# CPU_ROM_TABLE register map
Vendor: Texas Instruments
Peripheral module from a debugger description file (folder UCD3138R032RJA).
Registers are 32-bit, read-only, reset 0x0 unless marked. A register's access mark holds for its fields unless they carry their own. Offsets are as the file gives them; lines under a group give offsets from that group; [hi:lo] are bit positions; {n}, {i} and the like mark numbered series; 'fields as' and 'values as' point back to an identical list; <NAME> marks a mode.

## CPU_ROM_TABLE
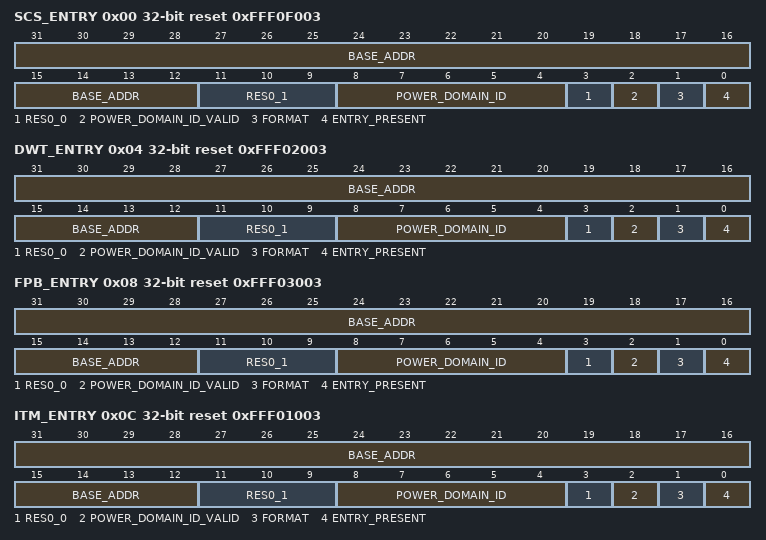
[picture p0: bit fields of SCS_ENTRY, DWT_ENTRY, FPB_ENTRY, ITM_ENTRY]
0x00 SCS_ENTRY reset 0xFFF0F003 — SCS component
  [31:12] BASE_ADDR — Base address for master interface 0. Bit[31] is always 0.
  [11:9] RES0_1 — Reserved, RES0
  [8:4] POWER_DOMAIN_ID — Indicates the power domain ID of the component. This field is only valid when bit[2] of this register is 0b1. Otherwise this field is 0b1.
  [3] RES0_0 — Reserved, RES0
  [2] POWER_DOMAIN_ID_VALID — Indicates whether there is a power domain ID specified in the ROM Table entry
  [1] FORMAT — Indicates the ROM table entry format
  [0] ENTRY_PRESENT — Indicates whether there is a valid ROM entry at this location.
0x04 DWT_ENTRY reset 0xFFF02003 — Data watchpoint unit
  fields as SCS_ENTRY
0x08 FPB_ENTRY reset 0xFFF03003 — Flash Patch and Breakpoint unit
  fields as SCS_ENTRY
0x0C ITM_ENTRY reset 0xFFF01003 — never implemented
  fields as SCS_ENTRY
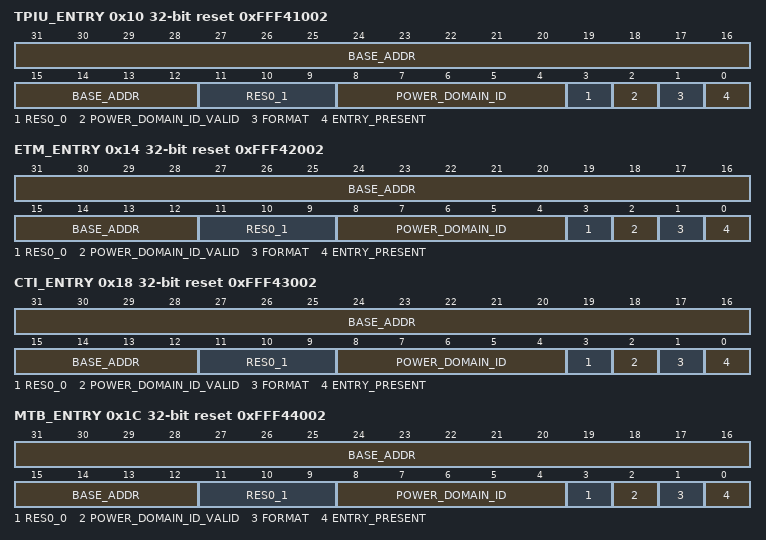
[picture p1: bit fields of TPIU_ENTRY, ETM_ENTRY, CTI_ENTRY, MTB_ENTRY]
0x10 TPIU_ENTRY reset 0xFFF41002 — Trace Port Interface unit
  fields as SCS_ENTRY
0x14 ETM_ENTRY reset 0xFFF42002 — Embedded Trace Macrocell
  fields as SCS_ENTRY
0x18 CTI_ENTRY reset 0xFFF43002 — Cross Trigger Interface
  fields as SCS_ENTRY
0x1C MTB_ENTRY reset 0xFFF44002 — Micro Trace Buffer
  fields as SCS_ENTRY
0x20 END_MARKER — end of the rom for discovery
0xFCC SYSTEM_ACCESS_ENTRY reset 0x1 — SYSTEM ACCESS
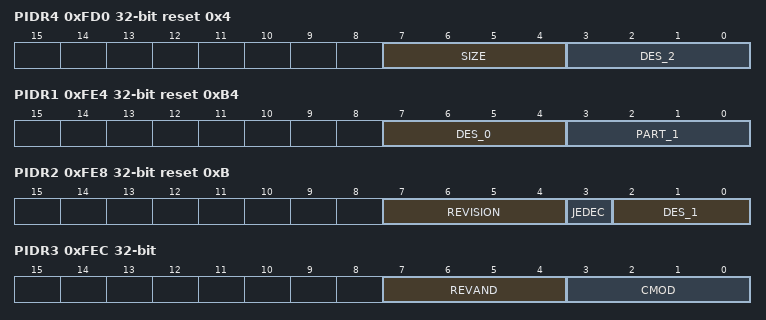
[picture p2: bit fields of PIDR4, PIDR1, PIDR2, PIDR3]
0xFD0 PIDR4 reset 0x4 — CoreSight Periperal ID4
  [7:4] SIZE — Always 0b0000. Indicates that the device only occupies 4KB of memory
  [3:0] DES_2 — Together, PIDR1.DES_0, PIDR2.DES_1, and PIDR4.DES_2 identify the designer of the component.
{0xFC0+4i} PIDR{i} (i=5..7) — CoreSight Periperal ID{i}
0xFE0 PIDR0 reset 0xC9 — CoreSight Periperal ID0
  [7:0] PART_0 — Bits[7:0] of the 12-bit part number of the component. The designer of the component assigns this part number.
0xFE4 PIDR1 reset 0xB4 — CoreSight Periperal ID1
  [7:4] DES_0 — Together, PIDR1.DES_0, PIDR2.DES_1, and PIDR4.DES_2 identify the designer of the component.
  [3:0] PART_1 — Bits[11:8] of the 12-bit part number of the component. The designer of the component assigns this part number.
0xFE8 PIDR2 reset 0xB — CoreSight Periperal ID2
  [7:4] REVISION — This device is at r1p0
  [3] JEDEC — Always 1. Indicates that the JEDEC-assigned designer ID is used.
  [2:0] DES_1 — Together, PIDR1.DES_0, PIDR2.DES_1, and PIDR4.DES_2 identify the designer of the component.
0xFEC PIDR3 — CoreSight Periperal ID3
  [7:4] REVAND — Indicates minor errata fixes specific to the revision of the component being used, for example metal fixes after implementation. In most cases, this field is 0b0000. ARM recommends that the component designers ensure that a metal fix can change this field if required, for example, by driving it from registers that reset to 0b0000.
  [3:0] CMOD — Customer Modified. Indicates whether the customer has modified the behavior of the component. In most cases, this field is 0b0000. Customers change this value when they make authorized modifications to this component.
0xFF0 CIDR0 reset 0xD — CoreSight Component ID0
  [7:0] PRMBL_0 — Preamble[0]. Contains bits[7:0] of the component identification code
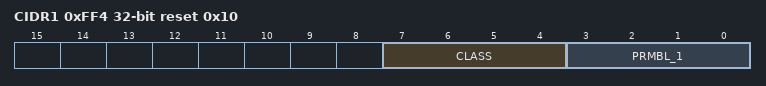
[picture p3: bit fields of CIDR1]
0xFF4 CIDR1 reset 0x10 — CoreSight Component ID1
  [7:4] CLASS — Class of the component, for example, whether the component is a ROM table or a generic CoreSight component. Contains bits[15:12] of the component identification code.
  [3:0] PRMBL_1 — Preamble[1]. Contains bits[11:8] of the component identification code.
0xFF8 CIDR2 reset 0x5 — CoreSight Component ID2
  [7:0] PRMBL_2 — Preamble[2]. Contains bits[23:16] of the component identification code.
0xFFC CIDR3 reset 0xB1 — CoreSight Component ID3
  [7:0] PRMBL_3 — Preamble[3]. Contains bits[31:24] of the component identification code.
